AUTOSAR XML (schema 4-2-2)
package /STELLANTIS/EPT/ASWCs
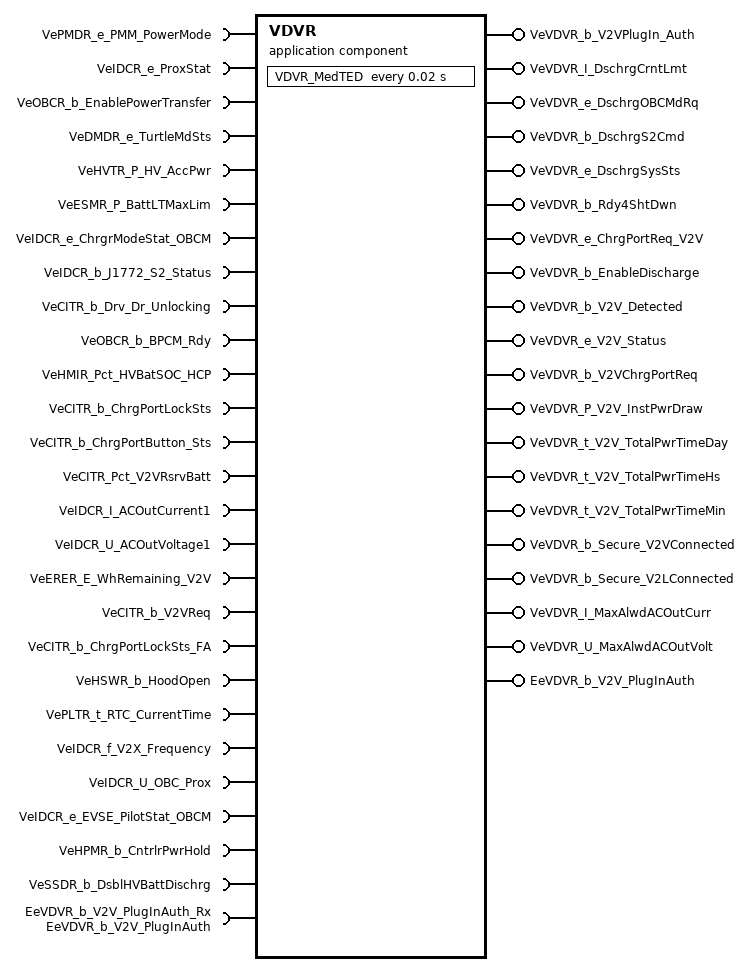
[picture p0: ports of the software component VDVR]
  application sw component type VDVR
    26 x require port:
      VePMDR_e_PMM_PowerMode: variation-point={short-label=vpVePMDR_e_PMM_PowerMode, sw-syscond=1}, nonqueued-receiver-com-spec{data-element=Value, init-value=CePMDR_e_PowerMode_Off}, required-interface=VePMDR_e_PMM_PowerMode
      VeIDCR_e_ProxStat: variation-point={short-label=vpVeIDCR_e_ProxStat, sw-syscond=1}, nonqueued-receiver-com-spec{data-element=Value, init-value=CeOBCR_e_ProxLo_OBCM}, required-interface=VeIDCR_e_ProxStat
      VeOBCR_b_EnablePowerTransfer: variation-point={short-label=vpVeOBCR_b_EnablePowerTransfer, sw-syscond=1}, nonqueued-receiver-com-spec{data-element=Value, init-value=0}, required-interface=VeOBCR_b_EnablePowerTransfer
      VeDMDR_e_TurtleMdSts: variation-point={short-label=vpVeDMDR_e_TurtleMdSts, sw-syscond=1}, nonqueued-receiver-com-spec{data-element=Value, init-value=CeDMDR_e_No_Turtle_Mode}, required-interface=VeDMDR_e_TurtleMdSts
      VeHVTR_P_HV_AccPwr: variation-point={short-label=vpVeHVTR_P_HV_AccPwr, sw-syscond=1}, nonqueued-receiver-com-spec{data-element=Value, init-value=0}, required-interface=VeHVTR_P_HV_AccPwr
      VeESMR_P_BattLTMaxLim: variation-point={short-label=vpVeESMR_P_BattLTMaxLim, sw-syscond=1}, nonqueued-receiver-com-spec{data-element=Value, init-value=0}, required-interface=VeESMR_P_BattLTMaxLim
      VeIDCR_e_ChrgrModeStat_OBCM: variation-point={short-label=vpVeIDCR_e_ChrgrModeStat_OBCM, sw-syscond=1}, nonqueued-receiver-com-spec{data-element=Value, init-value=CeOBCR_e_Idle_OBCM}, required-interface=VeIDCR_e_ChrgrModeStat_OBCM
      VeIDCR_b_J1772_S2_Status: variation-point={short-label=vpVeIDCR_b_J1772_S2_Status, sw-syscond=1}, nonqueued-receiver-com-spec{data-element=Value, init-value=0}, required-interface=VeIDCR_b_J1772_S2_Status
      VeCITR_b_Drv_Dr_Unlocking: variation-point={short-label=vpVeCITR_b_Drv_Dr_Unlocking, sw-syscond=1}, nonqueued-receiver-com-spec{data-element=Value, init-value=0}, required-interface=VeCITR_b_Drv_Dr_Unlocking
      VeOBCR_b_BPCM_Rdy: variation-point={short-label=vpVeOBCR_b_BPCM_Rdy, sw-syscond=1}, nonqueued-receiver-com-spec{data-element=Value, init-value=0}, required-interface=VeOBCR_b_BPCM_Rdy
      VeHMIR_Pct_HVBatSOC_HCP: variation-point={short-label=vpVeHMIR_Pct_HVBatSOC_HCP, sw-syscond=1}, nonqueued-receiver-com-spec{data-element=Value, init-value=0}, required-interface=VeHMIR_Pct_HVBatSOC_HCP
      VeCITR_b_ChrgPortLockSts: variation-point={short-label=vpVeCITR_b_ChrgPortLockSts, sw-syscond=1}, nonqueued-receiver-com-spec{data-element=Value, init-value=0}, required-interface=VeCITR_b_ChrgPortLockSts
      VeCITR_b_ChrgPortButton_Sts: variation-point={short-label=vpVeCITR_b_ChrgPortButton_Sts, sw-syscond=1}, nonqueued-receiver-com-spec{data-element=Value, init-value=0}, required-interface=VeCITR_b_ChrgPortButton_Sts
      VeCITR_Pct_V2VRsrvBatt: variation-point={short-label=vpVeCITR_Pct_V2VRsrvBatt, sw-syscond=1}, nonqueued-receiver-com-spec{data-element=Value, init-value=0}, required-interface=VeCITR_Pct_V2VRsrvBatt
      VeIDCR_I_ACOutCurrent1: variation-point={short-label=vpVeIDCR_I_ACOutCurrent1, sw-syscond=1}, nonqueued-receiver-com-spec{data-element=Value, init-value=0}, required-interface=VeIDCR_I_ACOutCurrent1
      VeIDCR_U_ACOutVoltage1: variation-point={short-label=vpVeIDCR_U_ACOutVoltage1, sw-syscond=1}, nonqueued-receiver-com-spec{data-element=Value, init-value=0}, required-interface=VeIDCR_U_ACOutVoltage1
      VeERER_E_WhRemaining_V2V: variation-point={short-label=vpVeERER_E_WhRemaining_V2V, sw-syscond=1}, nonqueued-receiver-com-spec{data-element=Value, init-value=0}, required-interface=VeERER_E_WhRemaining_V2V
      VeCITR_b_V2VReq: variation-point={short-label=vpVeCITR_b_V2VReq, sw-syscond=1}, nonqueued-receiver-com-spec{data-element=Value, init-value=0}, required-interface=VeCITR_b_V2VReq
      VeCITR_b_ChrgPortLockSts_FA: variation-point={short-label=vpVeCITR_b_ChrgPortLockSts_FA, sw-syscond=1}, nonqueued-receiver-com-spec{data-element=Value, init-value=0}, required-interface=VeCITR_b_ChrgPortLockSts_FA
      VeHSWR_b_HoodOpen: variation-point={short-label=vpVeHSWR_b_HoodOpen, sw-syscond=1}, nonqueued-receiver-com-spec{data-element=Value, init-value=0}, required-interface=VeHSWR_b_HoodOpen
      VePLTR_t_RTC_CurrentTime: variation-point={short-label=vpVePLTR_t_RTC_CurrentTime, sw-syscond=1}, nonqueued-receiver-com-spec{data-element=Value, init-value=0}, required-interface=VePLTR_t_RTC_CurrentTime
      VeIDCR_f_V2X_Frequency: variation-point={short-label=vpVeIDCR_f_V2X_Frequency, sw-syscond=1}, nonqueued-receiver-com-spec{data-element=Value, init-value=0}, required-interface=VeIDCR_f_V2X_Frequency
      VeIDCR_U_OBC_Prox: variation-point={short-label=vpVeIDCR_U_OBC_Prox, sw-syscond=1}, nonqueued-receiver-com-spec{data-element=Value, init-value=0}, required-interface=VeIDCR_U_OBC_Prox
      VeIDCR_e_EVSE_PilotStat_OBCM: variation-point={short-label=vpVeIDCR_e_EVSE_PilotStat_OBCM, sw-syscond=1}, nonqueued-receiver-com-spec{data-element=Value, init-value=CeOBCR_e_NO_EVSE_OBCM}, required-interface=VeIDCR_e_EVSE_PilotStat_OBCM
      VeHPMR_b_CntrlrPwrHold: variation-point={short-label=vpVeHPMR_b_CntrlrPwrHold, sw-syscond=1}, nonqueued-receiver-com-spec{data-element=Value, init-value=0}, required-interface=VeHPMR_b_CntrlrPwrHold
      VeSSDR_b_DsblHVBattDischrg: variation-point={short-label=vpVeSSDR_b_DsblHVBattDischrg, sw-syscond=1}, nonqueued-receiver-com-spec{data-element=Value, init-value=0}, required-interface=VeSSDR_b_DsblHVBattDischrg
    19 x provide port:
      VeVDVR_b_V2VPlugIn_Auth: nonqueued-sender-com-spec{data-element=Value, init-value=0}, provided-interface=VeVDVR_b_V2VPlugIn_Auth
      VeVDVR_I_DschrgCrntLmt: nonqueued-sender-com-spec{data-element=Value, init-value=0}, provided-interface=VeVDVR_I_DschrgCrntLmt
      VeVDVR_e_DschrgOBCMdRq: nonqueued-sender-com-spec{data-element=Value, init-value=CeOBCR_e_Idle_OBCMdRq}, provided-interface=VeVDVR_e_DschrgOBCMdRq
      VeVDVR_b_DschrgS2Cmd: nonqueued-sender-com-spec{data-element=Value, init-value=0}, provided-interface=VeVDVR_b_DschrgS2Cmd
      VeVDVR_e_DschrgSysSts: nonqueued-sender-com-spec{data-element=Value, init-value=CeVTLR_e_DschrgInactv}, provided-interface=VeVDVR_e_DschrgSysSts
      VeVDVR_b_Rdy4ShtDwn: nonqueued-sender-com-spec{data-element=Value, init-value=0}, provided-interface=VeVDVR_b_Rdy4ShtDwn
      VeVDVR_e_ChrgPortReq_V2V: nonqueued-sender-com-spec{data-element=Value, init-value=CeOBCR_e_PortNoRequest}, provided-interface=VeVDVR_e_ChrgPortReq_V2V
      VeVDVR_b_EnableDischarge: nonqueued-sender-com-spec{data-element=Value, init-value=0}, provided-interface=VeVDVR_b_EnableDischarge
      VeVDVR_b_V2V_Detected: nonqueued-sender-com-spec{data-element=Value, init-value=0}, provided-interface=VeVDVR_b_V2V_Detected
      VeVDVR_e_V2V_Status: nonqueued-sender-com-spec{data-element=Value, init-value=CeVDVR_e_Inctv}, provided-interface=VeVDVR_e_V2V_Status
      VeVDVR_b_V2VChrgPortReq: nonqueued-sender-com-spec{data-element=Value, init-value=0}, provided-interface=VeVDVR_b_V2VChrgPortReq
      VeVDVR_P_V2V_InstPwrDraw: nonqueued-sender-com-spec{data-element=Value, init-value=0}, provided-interface=VeVDVR_P_V2V_InstPwrDraw
      VeVDVR_t_V2V_TotalPwrTimeDay: nonqueued-sender-com-spec{data-element=Value, init-value=0}, provided-interface=VeVDVR_t_V2V_TotalPwrTimeDay
      VeVDVR_t_V2V_TotalPwrTimeHs: nonqueued-sender-com-spec{data-element=Value, init-value=0}, provided-interface=VeVDVR_t_V2V_TotalPwrTimeHs
      VeVDVR_t_V2V_TotalPwrTimeMin: nonqueued-sender-com-spec{data-element=Value, init-value=0}, provided-interface=VeVDVR_t_V2V_TotalPwrTimeMin
      VeVDVR_b_Secure_V2VConnected: nonqueued-sender-com-spec{data-element=Value, init-value=0}, provided-interface=VeVDVR_b_Secure_V2VConnected
      VeVDVR_b_Secure_V2LConnected: nonqueued-sender-com-spec{data-element=Value, init-value=0}, provided-interface=VeVDVR_b_Secure_V2LConnected
      VeVDVR_I_MaxAlwdACOutCurr: nonqueued-sender-com-spec{data-element=Value, init-value=0}, provided-interface=VeVDVR_I_MaxAlwdACOutCurr
      VeVDVR_U_MaxAlwdACOutVolt: nonqueued-sender-com-spec{data-element=Value, init-value=0}, provided-interface=VeVDVR_U_MaxAlwdACOutVolt
    require port EeVDVR_b_V2V_PlugInAuth_Rx: variation-point={short-label=vpEeVDVR_b_V2V_PlugInAuth_Rx, sw-syscond=1}, nv-require-com-spec{init-value=0, variable=EeVDVR_b_V2V_PlugInAuth}, required-interface=EeVDVR_b_V2V_PlugInAuth
    provide port EeVDVR_b_V2V_PlugInAuth: variation-point={short-label=vpEeVDVR_b_V2V_PlugInAuth, sw-syscond=1}, nv-provide-com-spec{ram-block-init-value=0, variable=EeVDVR_b_V2V_PlugInAuth}, provided-interface=EeVDVR_b_V2V_PlugInAuth
    behavior IB_VDVR: data-type-mapping=msADTtoIDTMapping, handle-termination-and-restart=NO-SUPPORT, included-data-type-set=data-type=[TeVDVR_e_DischrgSt, TeVDVR_e_Secure_Conn_VtoX]
      timing event Event_MedTED: start-on-event=VDVR_MedTED, period=0.02
      init event Event_VDVR_ac_Init: start-on-event=VDVR_ac_Init
      init event Event_PwrOn: start-on-event=VDVR_PwrOn
      init event Event_PwrOff: start-on-event=VDVR_PwrOff
      4 x runnable:
        VDVR_ac_Init
          data-send-points:
            4 x access:
              OUT_VeVDVR_e_DschrgOBCMdRq_Value: accessed-variable=VeVDVR_e_DschrgOBCMdRq.Value
              OUT_VeVDVR_e_DschrgSysSts_Value: accessed-variable=VeVDVR_e_DschrgSysSts.Value
              OUT_VeVDVR_e_ChrgPortReq_V2V_Value: accessed-variable=VeVDVR_e_ChrgPortReq_V2V.Value
              OUT_VeVDVR_e_V2V_Status_Value: accessed-variable=VeVDVR_e_V2V_Status.Value
        VDVR_PwrOn
          data-receive-point-by-arguments:
            access IN_EeVDVR_b_V2V_PlugInAuth_Rx_EeVDVR_b_V2V_PlugInAuth: accessed-variable=EeVDVR_b_V2V_PlugInAuth_Rx.EeVDVR_b_V2V_PlugInAuth, variation-point={short-label=vpIN_EeVDVR_b_V2V_PlugInAuth_Rx_EeVDVR_b_V2V_PlugInAuth, sw-syscond=1}
          data-send-points:
            19 x access:
              OUT_VeVDVR_b_V2VPlugIn_Auth_Value: accessed-variable=VeVDVR_b_V2VPlugIn_Auth.Value
              OUT_VeVDVR_I_DschrgCrntLmt_Value: accessed-variable=VeVDVR_I_DschrgCrntLmt.Value
              OUT_VeVDVR_e_DschrgOBCMdRq_Value: accessed-variable=VeVDVR_e_DschrgOBCMdRq.Value
              OUT_VeVDVR_b_DschrgS2Cmd_Value: accessed-variable=VeVDVR_b_DschrgS2Cmd.Value
              OUT_VeVDVR_e_DschrgSysSts_Value: accessed-variable=VeVDVR_e_DschrgSysSts.Value
              OUT_VeVDVR_b_Rdy4ShtDwn_Value: accessed-variable=VeVDVR_b_Rdy4ShtDwn.Value
              OUT_VeVDVR_e_ChrgPortReq_V2V_Value: accessed-variable=VeVDVR_e_ChrgPortReq_V2V.Value
              OUT_VeVDVR_b_EnableDischarge_Value: accessed-variable=VeVDVR_b_EnableDischarge.Value
              OUT_VeVDVR_b_V2V_Detected_Value: accessed-variable=VeVDVR_b_V2V_Detected.Value
              OUT_VeVDVR_e_V2V_Status_Value: accessed-variable=VeVDVR_e_V2V_Status.Value
              OUT_VeVDVR_b_V2VChrgPortReq_Value: accessed-variable=VeVDVR_b_V2VChrgPortReq.Value
              OUT_VeVDVR_P_V2V_InstPwrDraw_Value: accessed-variable=VeVDVR_P_V2V_InstPwrDraw.Value
              OUT_VeVDVR_t_V2V_TotalPwrTimeDay_Value: accessed-variable=VeVDVR_t_V2V_TotalPwrTimeDay.Value
              OUT_VeVDVR_t_V2V_TotalPwrTimeHs_Value: accessed-variable=VeVDVR_t_V2V_TotalPwrTimeHs.Value
              OUT_VeVDVR_t_V2V_TotalPwrTimeMin_Value: accessed-variable=VeVDVR_t_V2V_TotalPwrTimeMin.Value
              OUT_VeVDVR_b_Secure_V2VConnected_Value: accessed-variable=VeVDVR_b_Secure_V2VConnected.Value
              OUT_VeVDVR_b_Secure_V2LConnected_Value: accessed-variable=VeVDVR_b_Secure_V2LConnected.Value
              OUT_VeVDVR_I_MaxAlwdACOutCurr_Value: accessed-variable=VeVDVR_I_MaxAlwdACOutCurr.Value
              OUT_VeVDVR_U_MaxAlwdACOutVolt_Value: accessed-variable=VeVDVR_U_MaxAlwdACOutVolt.Value
        VDVR_MedTED: variation-point={short-label=vpVDVR_MedTED, sw-syscond=1}
          data-receive-point-by-arguments:
            26 x access:
              IN_VeCITR_Pct_V2VRsrvBatt_Value: accessed-variable=VeCITR_Pct_V2VRsrvBatt.Value, variation-point={short-label=vpIN_VeCITR_Pct_V2VRsrvBatt_Value, sw-syscond=1}
              IN_VeCITR_b_ChrgPortButton_Sts_Value: accessed-variable=VeCITR_b_ChrgPortButton_Sts.Value, variation-point={short-label=vpIN_VeCITR_b_ChrgPortButton_Sts_Value, sw-syscond=1}
              IN_VeCITR_b_ChrgPortLockSts_Value: accessed-variable=VeCITR_b_ChrgPortLockSts.Value, variation-point={short-label=vpIN_VeCITR_b_ChrgPortLockSts_Value, sw-syscond=1}
              IN_VeCITR_b_ChrgPortLockSts_FA_Value: accessed-variable=VeCITR_b_ChrgPortLockSts_FA.Value, variation-point={short-label=vpIN_VeCITR_b_ChrgPortLockSts_FA_Value, sw-syscond=1}
              IN_VeCITR_b_Drv_Dr_Unlocking_Value: accessed-variable=VeCITR_b_Drv_Dr_Unlocking.Value, variation-point={short-label=vpIN_VeCITR_b_Drv_Dr_Unlocking_Value, sw-syscond=1}
              IN_VeCITR_b_V2VReq_Value: accessed-variable=VeCITR_b_V2VReq.Value, variation-point={short-label=vpIN_VeCITR_b_V2VReq_Value, sw-syscond=1}
              IN_VeDMDR_e_TurtleMdSts_Value: accessed-variable=VeDMDR_e_TurtleMdSts.Value, variation-point={short-label=vpIN_VeDMDR_e_TurtleMdSts_Value, sw-syscond=1}
              IN_VeERER_E_WhRemaining_V2V_Value: accessed-variable=VeERER_E_WhRemaining_V2V.Value, variation-point={short-label=vpIN_VeERER_E_WhRemaining_V2V_Value, sw-syscond=1}
              IN_VeESMR_P_BattLTMaxLim_Value: accessed-variable=VeESMR_P_BattLTMaxLim.Value, variation-point={short-label=vpIN_VeESMR_P_BattLTMaxLim_Value, sw-syscond=1}
              IN_VeHMIR_Pct_HVBatSOC_HCP_Value: accessed-variable=VeHMIR_Pct_HVBatSOC_HCP.Value, variation-point={short-label=vpIN_VeHMIR_Pct_HVBatSOC_HCP_Value, sw-syscond=1}
              IN_VeHPMR_b_CntrlrPwrHold_Value: accessed-variable=VeHPMR_b_CntrlrPwrHold.Value, variation-point={short-label=vpIN_VeHPMR_b_CntrlrPwrHold_Value, sw-syscond=1}
              IN_VeHSWR_b_HoodOpen_Value: accessed-variable=VeHSWR_b_HoodOpen.Value, variation-point={short-label=vpIN_VeHSWR_b_HoodOpen_Value, sw-syscond=1}
              IN_VeHVTR_P_HV_AccPwr_Value: accessed-variable=VeHVTR_P_HV_AccPwr.Value, variation-point={short-label=vpIN_VeHVTR_P_HV_AccPwr_Value, sw-syscond=1}
              IN_VeIDCR_I_ACOutCurrent1_Value: accessed-variable=VeIDCR_I_ACOutCurrent1.Value, variation-point={short-label=vpIN_VeIDCR_I_ACOutCurrent1_Value, sw-syscond=1}
              IN_VeIDCR_U_ACOutVoltage1_Value: accessed-variable=VeIDCR_U_ACOutVoltage1.Value, variation-point={short-label=vpIN_VeIDCR_U_ACOutVoltage1_Value, sw-syscond=1}
              IN_VeIDCR_U_OBC_Prox_Value: accessed-variable=VeIDCR_U_OBC_Prox.Value, variation-point={short-label=vpIN_VeIDCR_U_OBC_Prox_Value, sw-syscond=1}
              IN_VeIDCR_b_J1772_S2_Status_Value: accessed-variable=VeIDCR_b_J1772_S2_Status.Value, variation-point={short-label=vpIN_VeIDCR_b_J1772_S2_Status_Value, sw-syscond=1}
              IN_VeIDCR_e_ChrgrModeStat_OBCM_Value: accessed-variable=VeIDCR_e_ChrgrModeStat_OBCM.Value, variation-point={short-label=vpIN_VeIDCR_e_ChrgrModeStat_OBCM_Value, sw-syscond=1}
              IN_VeIDCR_e_EVSE_PilotStat_OBCM_Value: accessed-variable=VeIDCR_e_EVSE_PilotStat_OBCM.Value, variation-point={short-label=vpIN_VeIDCR_e_EVSE_PilotStat_OBCM_Value, sw-syscond=1}
              IN_VeIDCR_e_ProxStat_Value: accessed-variable=VeIDCR_e_ProxStat.Value, variation-point={short-label=vpIN_VeIDCR_e_ProxStat_Value, sw-syscond=1}
              IN_VeIDCR_f_V2X_Frequency_Value: accessed-variable=VeIDCR_f_V2X_Frequency.Value, variation-point={short-label=vpIN_VeIDCR_f_V2X_Frequency_Value, sw-syscond=1}
              IN_VeOBCR_b_BPCM_Rdy_Value: accessed-variable=VeOBCR_b_BPCM_Rdy.Value, variation-point={short-label=vpIN_VeOBCR_b_BPCM_Rdy_Value, sw-syscond=1}
              IN_VeOBCR_b_EnablePowerTransfer_Value: accessed-variable=VeOBCR_b_EnablePowerTransfer.Value, variation-point={short-label=vpIN_VeOBCR_b_EnablePowerTransfer_Value, sw-syscond=1}
              IN_VePLTR_t_RTC_CurrentTime_Value: accessed-variable=VePLTR_t_RTC_CurrentTime.Value, variation-point={short-label=vpIN_VePLTR_t_RTC_CurrentTime_Value, sw-syscond=1}
              IN_VePMDR_e_PMM_PowerMode_Value: accessed-variable=VePMDR_e_PMM_PowerMode.Value, variation-point={short-label=vpIN_VePMDR_e_PMM_PowerMode_Value, sw-syscond=1}
              IN_VeSSDR_b_DsblHVBattDischrg_Value: accessed-variable=VeSSDR_b_DsblHVBattDischrg.Value, variation-point={short-label=vpIN_VeSSDR_b_DsblHVBattDischrg_Value, sw-syscond=1}
          data-send-points:
            19 x access:
              OUT_VeVDVR_I_DschrgCrntLmt_Value: accessed-variable=VeVDVR_I_DschrgCrntLmt.Value
              OUT_VeVDVR_e_DschrgOBCMdRq_Value: accessed-variable=VeVDVR_e_DschrgOBCMdRq.Value
              OUT_VeVDVR_b_DschrgS2Cmd_Value: accessed-variable=VeVDVR_b_DschrgS2Cmd.Value
              OUT_VeVDVR_e_DschrgSysSts_Value: accessed-variable=VeVDVR_e_DschrgSysSts.Value
              OUT_VeVDVR_b_Rdy4ShtDwn_Value: accessed-variable=VeVDVR_b_Rdy4ShtDwn.Value
              OUT_VeVDVR_b_EnableDischarge_Value: accessed-variable=VeVDVR_b_EnableDischarge.Value
              OUT_VeVDVR_e_ChrgPortReq_V2V_Value: accessed-variable=VeVDVR_e_ChrgPortReq_V2V.Value
              OUT_VeVDVR_e_V2V_Status_Value: accessed-variable=VeVDVR_e_V2V_Status.Value
              OUT_VeVDVR_b_V2V_Detected_Value: accessed-variable=VeVDVR_b_V2V_Detected.Value
              OUT_VeVDVR_b_V2VPlugIn_Auth_Value: accessed-variable=VeVDVR_b_V2VPlugIn_Auth.Value
              OUT_VeVDVR_b_V2VChrgPortReq_Value: accessed-variable=VeVDVR_b_V2VChrgPortReq.Value
              OUT_VeVDVR_P_V2V_InstPwrDraw_Value: accessed-variable=VeVDVR_P_V2V_InstPwrDraw.Value
              OUT_VeVDVR_t_V2V_TotalPwrTimeDay_Value: accessed-variable=VeVDVR_t_V2V_TotalPwrTimeDay.Value
              OUT_VeVDVR_t_V2V_TotalPwrTimeHs_Value: accessed-variable=VeVDVR_t_V2V_TotalPwrTimeHs.Value
              OUT_VeVDVR_t_V2V_TotalPwrTimeMin_Value: accessed-variable=VeVDVR_t_V2V_TotalPwrTimeMin.Value
              OUT_VeVDVR_b_Secure_V2VConnected_Value: accessed-variable=VeVDVR_b_Secure_V2VConnected.Value
              OUT_VeVDVR_b_Secure_V2LConnected_Value: accessed-variable=VeVDVR_b_Secure_V2LConnected.Value
              OUT_VeVDVR_I_MaxAlwdACOutCurr_Value: accessed-variable=VeVDVR_I_MaxAlwdACOutCurr.Value
              OUT_VeVDVR_U_MaxAlwdACOutVolt_Value: accessed-variable=VeVDVR_U_MaxAlwdACOutVolt.Value
        VDVR_PwrOff: variation-point={short-label=vpVDVR_PwrOff, sw-syscond=1}
          data-send-points:
            access OUT_EeVDVR_b_V2V_PlugInAuth_EeVDVR_b_V2V_PlugInAuth: accessed-variable=EeVDVR_b_V2V_PlugInAuth.EeVDVR_b_V2V_PlugInAuth, variation-point={short-label=vpOUT_EeVDVR_b_V2V_PlugInAuth_EeVDVR_b_V2V_PlugInAuth, sw-syscond=1}
      variation point proxy Variant_VDVR_1: category=CONDITION, condition-access=1
